# R7FA6M3AH register map
Vendor: Renesas; Series: RA6; File version: 1.2
CPU: CM4 r0p1, little endian, MPU, FPU, VTOR, 4 interrupt priority bits
Registers are 32-bit, read-write, reset 0x0 unless marked. A register's access mark holds for its fields unless they carry their own. Offsets are from the block's base; [hi:lo] are bit positions.

## JPEG — JPEG Codec
Base 0x400E6000
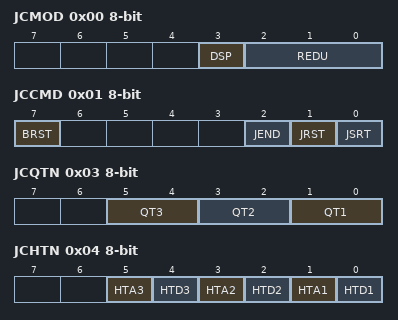
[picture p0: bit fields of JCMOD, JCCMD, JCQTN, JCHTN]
0x00 JCMOD 8-bit — JPEG Code Mode Register
  [3] DSP — Compression/Decompression Set Note: When changing between processing for compression and for decompression, be sure to reset this module in advance by setting the JCUSRST bit in the software reset control register 2 (SWRSTCR2) of the power,downmodes.
  [2:0] REDU — Pixel FormatNOTE: Read,only in Decompression.
0x01 JCCMD 8-bit wo reset not defined — JPEG Code Command Register
  [7] BRST — Bus Reset. NOTE: When this module is in operation, the bus reset command should not be issued.
  [2] JEND — Interrupt Request Clear Command This bit is valid only for the interrupt sources corresponding to bits INS6, INS5, and INS3 in JINTS0. To clear an interrupt request, set this bit to 1
  [1] JRST — JPEG Core Process Stop Clear CommandTo clear the process,stopped state caused by requests to read the image size and pixel format (enabled by the INT3 bit in JINTE0), set this bit to 1.
  [0] JSRT — JPEG Core Process Start CommandTo start JPEG core processing, set this bit to 1. Do not write this bit to 1 again while this module is in operation.
0x03 JCQTN 8-bit — JPEG Code Quantization Table Number Register
  [5:4] QT3 — Quantization table number for the third color component NOTE: Read,only in Decompression.
  [3:2] QT2 — Quantization table number for the second color component NOTE: Read,only in Decompression.
  [1:0] QT1 — Quantization table number for the first color componentNOTE: Read,only in Decompression.
0x04 JCHTN 8-bit — JPEG Code Huffman Table Number Register
  [5] HTA3 — Huffman table number (AC) for the third color componentNOTE: Read,only in Decompression.
  [4] HTD3 — Huffman table number (DC) for the third color component NOTE: Read,only in Decompression.
  [3] HTA2 — Huffman table number (AC) for the second color componentNOTE: Read,only in Decompression.
  [2] HTD2 — Huffman table number (DC) for the second color component NOTE: Read,only in Decompression.
  [1] HTA1 — Huffman table number (AC) for the first color componentNOTE: Read,only in Decompression.
  [0] HTD1 — Huffman table number (DC) for the first color component NOTE: Read,only in Decompression.
0x05 JCDRIU 8-bit — JPEG Code DRI Upper Register
  [7:0] DRIU — Upper Bytes of MCUs Preceding RST MarkerWhen both upper and lower bytes are set to 00h, neither a DRI nor an RST marker is placed.NOTE: Read,only in Decompression.
0x06 JCDRID 8-bit — JPEG Code DRI Lower Register
  [7:0] DRID — Lower Bytes of MCUs Preceding RST MarkerWhen both upper and lower bytes are set to 00h, neither a DRI nor an RST marker is placed.NOTE: Read,only in Decompression.
0x07 JCVSZU 8-bit — JPEG Code Vertical Size Upper Register
  [7:0] VSZU — Upper Bytes of Vertical Image SizeIn decompression process, a downloaded value from the JPEG coded data is set. NOTE: Read,only in Decompression.
0x08 JCVSZD 8-bit — JPEG Code Vertical Size Lower Register
  [7:0] VSZD — Lower Bytes of Vertical Image SizeIn decompression process, a downloaded value from the JPEG coded data is set. NOTE: Read,only in Decompression.
0x09 JCHSZU 8-bit — JPEG Code Horizontal Size Upper Register
  [7:0] HSZU — Upper Bytes of Horizontal Image SizeIn decompression process, a downloaded value from the JPEG coded data is set. NOTE: Read,only in Decompression.
0x0A JCHSZD 8-bit — JPEG Coded Horizontal Size Lower Register
  [7:0] HSZD — Lower Bytes of Horizontal Image SizeIn decompression process, a downloaded value from the JPEG coded data is set. NOTE: Read,only in Decompression.
0x0B JCDTCU 8-bit ro — JPEG Code Data Count Upper Register
  [7:0] DCU — Upper bytes of the counted amount of data to be compressed The values of this register are reset before compression starts.NOTE: Read,only in Decompression.
0x0C JCDTCM 8-bit ro — JPEG Code Data Count Middle Register
  [7:0] DCM — Middle bytes of the counted amount of data to be compressedThe values of this register are reset before compression starts. NOTE: Read,only in Decompression.
0x0D JCDTCD 8-bit ro — JPEG Code Data Count Lower Register
  [7:0] DCD — Lower bytes of the counted amount of data to be compressedThe values of this register are reset before compression starts.NOTE: Read,only in Decompression.
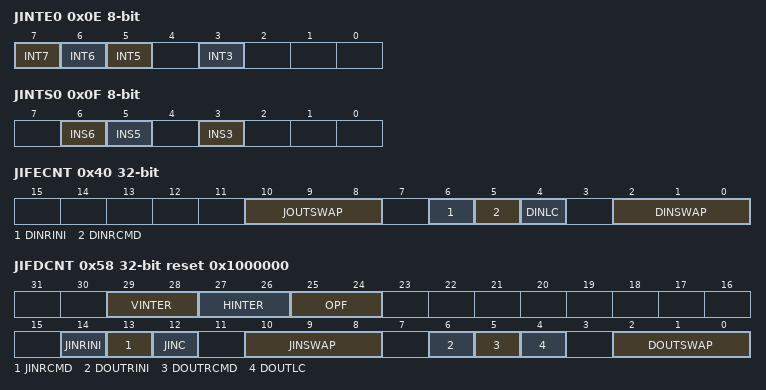
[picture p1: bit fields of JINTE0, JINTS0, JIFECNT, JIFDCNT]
0x0E JINTE0 8-bit — JPEG Interrupt Enable Register 0
  [7] INT7 — This bit enables an interrupt to be generated when the number of data in the restart interval of the Huffman,coding segment is not correct in decompression.When this bit is not set to enable interrupt generation, an error code is not returned.
  [6] INT6 — This bit enables an interrupt to be generated when the total number of data in the Huffman,coding segment is not correct in decompression. When this bit is not set to enable interrupt generation, an error code is not returned.
  [5] INT5 — This bit enables an interrupt to be generated when the final number of MCU data in the Huffman,coding segment is not correct in decompression. When this bit is not set to enable interrupt generation, an error code is not returned.
  [3] INT3 — This bit enables an interrupt to be generated when it has been determined that the image size and the subsampling setting of the compressed data can be read through analyzing the data.
0x0F JINTS0 8-bit — JPEG Interrupt Status Register 0
  [6] INS6 write-0-clears read-modifies — This bit is set to 1 when this module completes compression process normally.
  [5] INS5 write-0-clears read-modifies — This bit is set to 1 when a compressed data error occurs.
  [3] INS3 write-0-clears read-modifies — This bit is set to 1 when the image size and pixel format can be read. When an interrupt occurs, this module stops processing and the state is indicated by the JCRST register. To make this module resume processing, set the JPEG core process stop clear command bit (JRST) in JCCMD.
0x10 JCDERR 8-bit reset 0xA — JPEG Code Decode Error Register
  [3:0] ERR — Error Code (See tables )Identify the type of the error which has occurred in the compressed data analysis for decompression.
0x11 JCRST 8-bit ro — JPEG Code Reset Register
  [0] RST — Operating State
0x40 JIFECNT — JPEG Interface Compression Control Register
  [10:8] JOUTSWAP — Byte/Halfword/Word Swap Output coded data in compression is swapped.
  [6] DINRINI — Address Initialization when Resuming Input of Image Data Lines This bit is only valid when the count mode for stopping the input of image data lines is on. Set this bit before writing 1 to the data,line resume command bit.
  [5] DINRCMD wo — Input Image Data Lines Resume Command This bit is valid only when the count mode for stopping the input of image data lines is on. Setting this bit to 1 resumes reading input image data. This bit is always read as 0.
  [4] DINLC — Count Mode Setting for Stopping Input Image Data Lines
  [2:0] DINSWAP — Byte/Halfword Swap
0x44 JIFESA — JPEG Interface Compression Source Address Register
  [31:0] ESA — Input Image Data Source Address (in 8-byte units) The lower three bits should be set to 0.
0x48 JIFESOFST — JPEG Interface Compression Line Offset Register
  [14:0] ESMW — Input Image Data Lines Offset(in 8-byte units)The lower three bits should be set to 0.
0x4C JIFEDA — JPEG Interface Compression Destination Address Register
  [31:0] EDA — Input Image Data Lines Offset (in 8-byte units) The lower three bits should be set to 0.
0x50 JIFESLC reset 0xFFF8FFF8 — JPEG Interface Compression Source Line Count Register
  [15:0] LINES — Number of Input Image Data Lines to be Read (in 8-line units) The lower three bits should be set to 0.
0x58 JIFDCNT reset 0x1000000 — JPEG Interface Decompression Control Register
  [29:28] VINTER — Vertical SubsamplingSubsamples vertical output image data.
  [27:26] HINTER — Horizontal Subsampling Subsamples horizontal output image data.
  [25:24] OPF — Specifies output image data pixel format.
  [14] JINRINI — Address Initialization when Input Coded Data is Resumed This bit is only valid when the count mode for stopping the input of coded data is on. Set this bit before writing 1 to the data resume command bit.
  [13] JINRCMD wo — Input Coded Data Resume CommandThis bit is valid only when the count mode for stopping the input of coded data is on. Setting this bit to 1 resumes reading input coded data. This bit is always read as 0.
  [12] JINC — Count Mode Setting for Stopping Input Coded Data
  [10:8] JINSWAP — Byte/Word/Longword Swap Input coded data in decompression is swapped.
  [6] DOUTRINI — Address Initialization when Resuming Output of Image Data Lines This bit is only valid when the count mode for stopping the output of image data lines is on. Set this bit before writing 1 to the data,line resume command bit.
  [5] DOUTRCMD wo — Output Image Data Lines Resume Command This bit is valid only when the count mode for stopping the output of image data lines is on. Setting this bit to 1 resumes writing image data. This bit is always read as 0.
  [4] DOUTLC — Count Mode for Stopping Output Image Data Lines
  [2:0] DOUTSWAP — Byte/Word Swap Output image data in decompression is swapped.
0x5C JIFDSA — JPEG Interface Decompression Source Address Register
  [31:0] DSA — Input Coded Data Source AddressInput Coded Data Source Address (in 8-byte units) The lower three bits should be set to 0.
0x60 JIFDDOFST — JPEG Interface Decompression Line Offset Register
  [14:0] DDMW — Output Image Data Lines Offset (in 8-byte units) The lower three bits should be set to 0.
0x64 JIFDDA — JPEG Interface Decompression Destination Address Register
  [31:0] DDA — Output Image Data Destination Address (in 8-byte units) The lower three bits should be set to 0.
0x68 JIFDSDC reset 0xFFF8FFF8 — JPEG Interface Decompression Source Data Count Register
  [15:0] JDATAS — Amount of Input Coded Data to be Read (in 8-byte units) The lower three bits should be set to 0.
0x6C JIFDDLC reset 0xFFF8FFF8 — JPEG Interface Decompression Destination Line Count Register
  [15:0] LINES — Number of Input Image Lines to Be ReadThe lower three bits should be set to 0. These bits are read as0.Number of input image data lines to be read, in 8-line units.
0x70 JIFDADT — JPEG Interface Decompression alpha Set Register
  [7:0] ALPHA — Setting of the alpha value for output in ARGB8888 format.
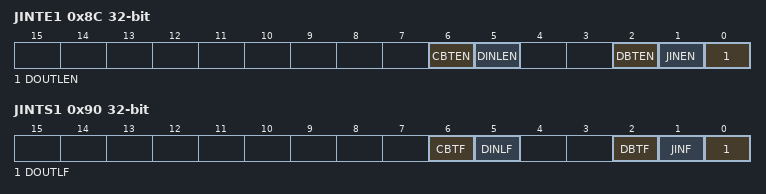
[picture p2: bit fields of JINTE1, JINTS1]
0x8C JINTE1 — JPEG Interrupt Enable Register 1
  [6] CBTEN — Enables or disables a data transfer processing interrupt request (JDTI) when the CBTF bit in JINTS1 is set to 1.
  [5] DINLEN — Enables or disables a data transfer processing interrupt request (JDTI) when the DINLF bit in JINTS1 is set to 1.
  [2] DBTEN — Enables or disables a data transfer processing interrupt request (JDTI) when the DBTF bit in JINTS1 is set to 1.
  [1] JINEN — Enables or disables a data transfer processing interrupt request (JDTI) when the JINF bit in JINTS1 is set to 1.
  [0] DOUTLEN — Enables or disables a data transfer processing interrupt request (JDTI) when the DOUTLF bit in JINTS1 is set to 1
0x90 JINTS1 — JPEG Interrupt Status Register 1
  [6] CBTF read-modifies — This bit is set to 1 when the last output coded data is written in compression.
  [5] DINLF read-modifies — This bit is set to 1 when the number of input image data lines indicated by JIFESLC is read in compression. This bit is valid only when the DINLC bit in JIFECNT is set to 1.
  [2] DBTF read-modifies — This bit is set to 1 when the last output image data is written in decompression.
  [1] JINF read-modifies — This bit is set to 1 when the amount of input coded data indicated by JIFDSDC is read in decompression. This bit is valid only when the JINC bit in JIFDCNT is set to 1.
  [0] DOUTLF read-modifies — In decompression, this bit is set to 1 when the number of lines of output image data indicated by JIFDDLC have been written. This bit is only valid when the DOUTLC bit in JIFDCNT is set to 1.
